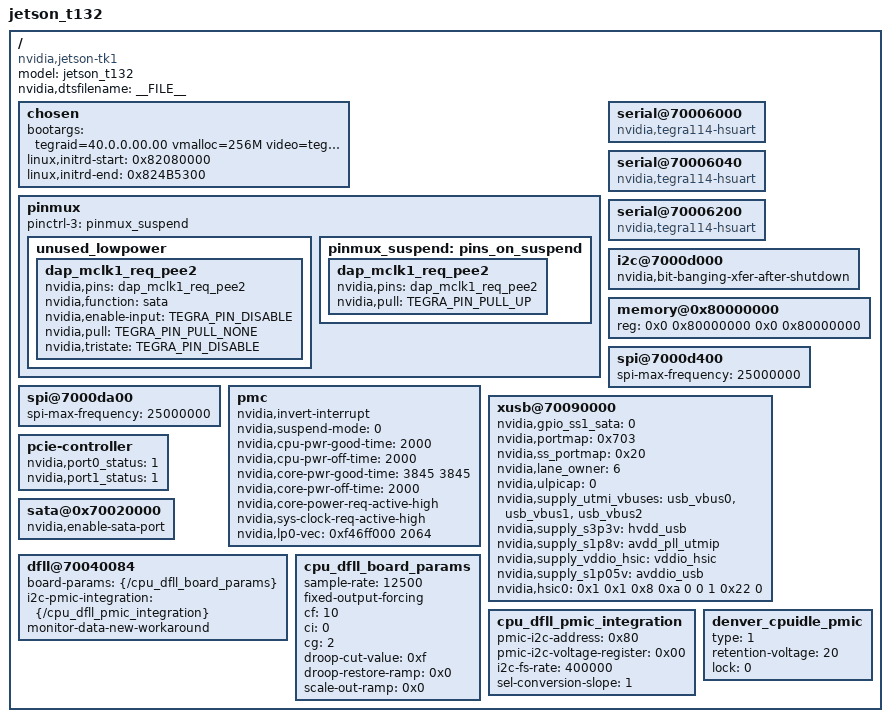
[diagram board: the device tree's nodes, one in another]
#include "tegra132.dtsi"
#include "tegra124-platforms/tegra124-tn8-keys-e1780-1100-a02.dtsi"
#include "tegra124-platforms/tegra124-jetson_tk1-gpio-pm375-0000-c00-00.dtsi"
#include "tegra124-platforms/tegra124-jetson_tk1-pinmux-pm375-0000-c00-00.dtsi"
#include "tegra124-platforms/tegra124-jetson_tk1-pmic-pm375-0000-c00-00.dtsi"
#include "tegra124-platforms/tegra124-jetson_tk1-fixed-pm375-0000-c00-00.dtsi"

/ {
	model = "jetson_t132";
	compatible = "nvidia,jetson-tk1","nvidia,laguna", "nvidia,tegra132";
	nvidia,dtsfilename = __FILE__;
	#address-cells = <2>;
	#size-cells = <2>;

	chosen {
		bootargs = "tegraid=40.0.0.00.00 vmalloc=256M video=tegrafb console=ttyS0,115200n8 earlyprintk";
		linux,initrd-start = <0x82080000>;
		linux,initrd-end = <0x824B5300>;
	};

	pinmux {
		pinctrl-names = "default", "drive", "unused", "suspend";
		pinctrl-3 = <&pinmux_suspend>;

		/* Change the pin dap_mclk1_req to required configurations */
		unused_lowpower {
			dap_mclk1_req_pee2 {
			nvidia,pins = "dap_mclk1_req_pee2";
			nvidia,function = "sata";
			nvidia,enable-input = <TEGRA_PIN_DISABLE>;
			nvidia,pull = <TEGRA_PIN_PULL_NONE>;
			nvidia,tristate = <TEGRA_PIN_DISABLE>;
			};
		};

		/* On suspend, make dap_mclk1_req to pull up */
		pinmux_suspend: pins_on_suspend {
		dap_mclk1_req_pee2 {
			nvidia,pins = "dap_mclk1_req_pee2";
			nvidia,pull = <TEGRA_PIN_PULL_UP>;
			};
		};
	};

        serial@70006000 {
                compatible = "nvidia,tegra114-hsuart";
                status = "okay";
        };

        serial@70006040 {
                compatible = "nvidia,tegra114-hsuart";
                status = "okay";
        };

        serial@70006200 {
                compatible = "nvidia,tegra114-hsuart";
                status = "okay";
        };

	i2c@7000d000 {
		nvidia,bit-banging-xfer-after-shutdown;
	};

	memory@0x80000000 {
		device_type = "memory";
		reg = <0x0 0x80000000 0x0 0x80000000>;
	};

	spi@7000d400 {
		status = "okay";
		spi-max-frequency = <25000000>;
	};

	spi@7000da00 {
		status = "okay";
		spi-max-frequency = <25000000>;
	};

	pmc {
		status = "okay";
		nvidia,invert-interrupt;
		nvidia,suspend-mode = <0>;
		nvidia,cpu-pwr-good-time = <2000>;
		nvidia,cpu-pwr-off-time = <2000>;
		nvidia,core-pwr-good-time = <3845 3845>;
		nvidia,core-pwr-off-time = <2000>;
		nvidia,core-power-req-active-high;
		nvidia,sys-clock-req-active-high;
		nvidia,lp0-vec = <0xf46ff000 2064>;
	};

	xusb@70090000 {
		/* nvidia,uses_external_pmic;
		nvidia,gpio_controls_muxed_ss_lanes; */
		nvidia,gpio_ss1_sata = <0>;
		nvidia,portmap = <0x703>; /* SSP0, SSP1 USB2P0, USB2P1, USBP2 */
		nvidia,ss_portmap = <0x20>; /* SSP0 on USB2P0, SSP1 on USB2P2 */
		nvidia,lane_owner = <6>; /* USB3P0 USB3P1 */
		nvidia,ulpicap = <0>; /* No ulpi support. can we remove */
		nvidia,supply_utmi_vbuses = "usb_vbus0", "usb_vbus1", "usb_vbus2";
		nvidia,supply_s3p3v = "hvdd_usb";
		nvidia,supply_s1p8v = "avdd_pll_utmip";
		nvidia,supply_vddio_hsic = "vddio_hsic";
		nvidia,supply_s1p05v = "avddio_usb";
		/* hsic config values in order defined in structure */
		nvidia,hsic0 = /bits/8 <0x1 0x1 0x8 0xa 0 0 1 0x22 0>;
		status = "okay";
	};

	pcie-controller {
		nvidia,port0_status = <1>;
		nvidia,port1_status = <1>;
		status = "okay";
	};

	sata@0x70020000 {
		status = "okay";
		nvidia,enable-sata-port;
	};

	dfll@70040084 {
		board-params = <&{/cpu_dfll_board_params}>;
		i2c-pmic-integration = <&{/cpu_dfll_pmic_integration}>;
		monitor-data-new-workaround;
		status = "okay";
	};

	cpu_dfll_board_params {
		sample-rate = <12500>;
		fixed-output-forcing;
		cf = <10>;
		ci = <0>;
		cg = <2>;
		droop-cut-value = <0xf>;
		droop-restore-ramp = <0x0>;
		scale-out-ramp = <0x0>;
	};

	cpu_dfll_pmic_integration {
		pmic-i2c-address = <0x80>;
		pmic-i2c-voltage-register = <0x00>;
		i2c-fs-rate = <400000>;
		sel-conversion-slope = <1>;
	};

	denver_cpuidle_pmic {
		type = <1>; /* AMS 3722/3723 */
		retention-voltage = <20>;
		lock = <0>;
	};


};
